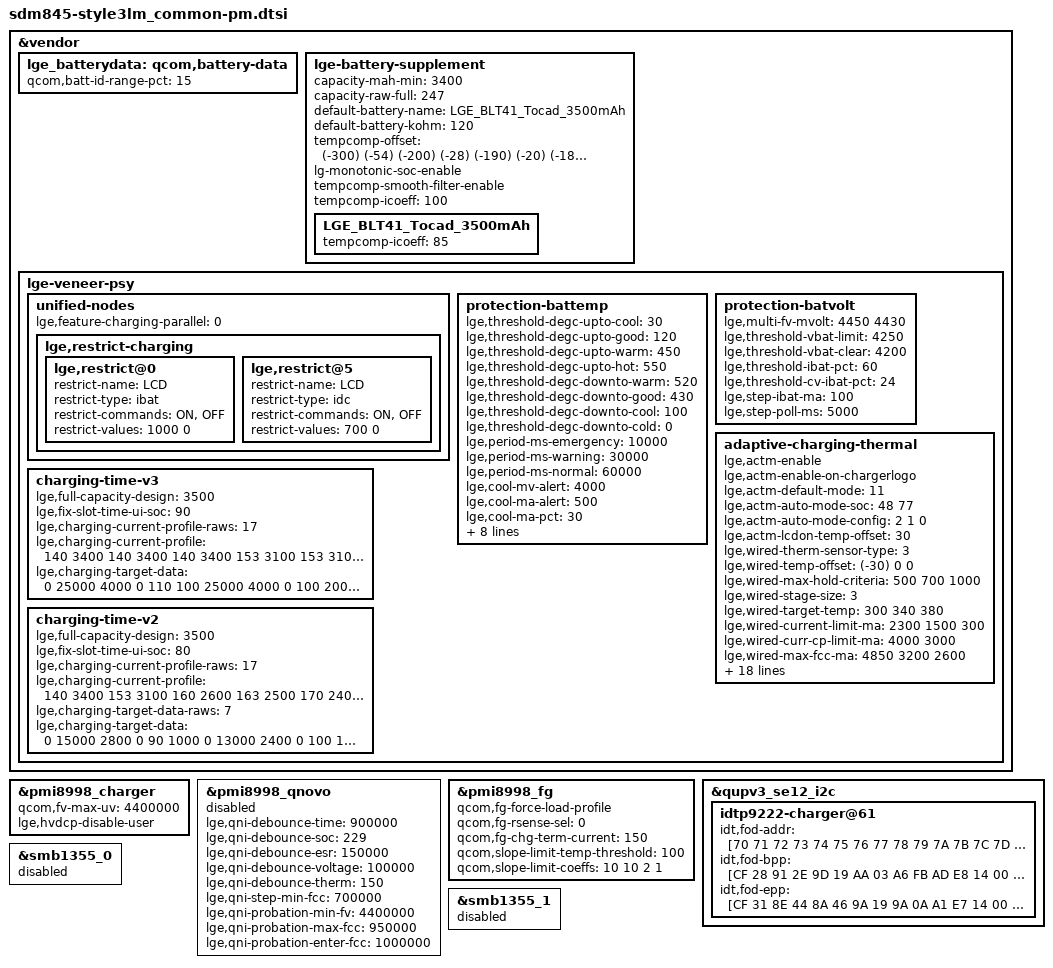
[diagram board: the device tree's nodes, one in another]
/* Copyright (c) 2017, The Linux Foundation. All rights reserved.
 *
 * This program is free software; you can redistribute it and/or modify
 * it under the terms of the GNU General Public License version 2 and
 * only version 2 as published by the Free Software Foundation.
 *
 * This program is distributed in the hope that it will be useful,
 * but WITHOUT ANY WARRANTY; without even the implied warranty of
 * MERCHANTABILITY or FITNESS FOR A PARTICULAR PURPOSE.  See the
 * GNU General Public License for more details.
 */

#include "../sdm845-judy_common/sdm845-judy_common-pm.dtsi"

&vendor {
	lge_batterydata: qcom,battery-data {
		qcom,batt-id-range-pct = <15>;
		#include "../../sdm845-battery/LGE_BLT41_Tocad_3500mAh.dtsi"
	};

	lge-battery-supplement {
		capacity-mah-min = <3400>;
		capacity-raw-full = <247>;

		default-battery-name = "LGE_BLT41_Tocad_3500mAh";
		default-battery-kohm = <120>;

		/* format : (temp index) (temp delta) */
		tempcomp-offset = <
			(-300) (-54)
			(-200) (-28)
			(-190) (-20)
			(-180) (-12)
			(-170) ( -8)
			(-160) ( -4)
			(-150)    0
			(-100)    8
			(-50)     9
			0         8
			50        6
			100       1
			150    ( -4)
			200    ( -9)
			250    (-12)
			300    (-21)
			350    (-26)
			400    (-31)
			450    (-34)
			500    (-32)
			550    (-30)
			600    (-24)
			700    (-11)
			800    (-11)
			900    (-11)
		>;

		//tempcomp-qnovo-charging;
		lg-monotonic-soc-enable;

		tempcomp-smooth-filter-enable;
		tempcomp-icoeff = <100>;
		LGE_BLT41_Tocad_3500mAh {
			tempcomp-icoeff = <85>;
		};
	};

	lge-veneer-psy {
		unified-nodes {
			lge,feature-charging-parallel = <0>;

			lge,restrict-charging {
				lge,restrict@0 {
					restrict-name = "LCD";
					restrict-type = "ibat";
					restrict-commands = "ON", "OFF";
					restrict-values = <1000      0>;
				};

				lge,restrict@5 {
					restrict-name = "LCD";
					restrict-type = "idc";
					restrict-commands = "ON", "OFF";
					restrict-values = < 700      0>;
				};
			};
		};

		protection-battemp {
			lge,threshold-degc-upto-cool = <30>;
			lge,threshold-degc-upto-good = <120>;
			lge,threshold-degc-upto-warm = <450>;
			lge,threshold-degc-upto-hot = <550>;
			lge,threshold-degc-downto-warm = <520>;
			lge,threshold-degc-downto-good = <430>;
			lge,threshold-degc-downto-cool = <100>;
			lge,threshold-degc-downto-cold = <0>;

			lge,period-ms-emergency	= <10000>;
			lge,period-ms-warning	= <30000>;
			lge,period-ms-normal	= <60000>;

		// parameters for warning status cool and warm
			lge,cool-mv-alert	= <4000>;
			lge,cool-ma-alert	= <500>;	// fixed 500 mA
			lge,cool-ma-pct		= <30>;		// means 0.3C rate

			lge,warm-mv-float	= <4000>;
			lge,warm-ma-pct		= <50>;		// means 0.5C rate

		// parameters for battery protection at chilly status
			lge,chilly-status-support;
			lge,chilly-degc-lowerbound = <0>;
			lge,chilly-degc-upperbound = <150>;
			lge,chilly-mv-alert	   = <4000>;
			lge,chilly-ma-alert	   = <500>;
			lge,chilly-ma-pct	   = <50>; 	// means 0.5C rate under batvol 4V
		};

		protection-batvolt {
			//lge,mulit-fv-enable;
			lge,multi-fv-mvolt = <4450 4430>;   // <CC_FV, CV_FV>

			lge,threshold-vbat-limit = <4250>;
			lge,threshold-vbat-clear = <4200>;
			lge,threshold-ibat-pct = <60>;      // means 0.6C rate
			lge,threshold-cv-ibat-pct = <24>;   // means 0.24C = 3400 * 0.24 = 816mA, CV = UI-100%

			lge,step-ibat-ma = <100>;
			lge,step-poll-ms = <5000>;
		};

		adaptive-charging-thermal {
			lge,actm-enable;
			//lge,actm-enable-cp-charging;                 // whether cp charging is supported.
			lge,actm-enable-on-chargerlogo;                // the actm operates charging first mode in chargerlogo
			lge,actm-default-mode = <11>;                  // 0-thermal first, 1-balanced, 2-charging first, 3-auto
			/*  actm auto mode description
			 *                     48%            77%
			 *    2-charging first  |  1-balacned  |  0-thermal first */
			lge,actm-auto-mode-soc = <48 77>;              // those values are raw soc.
			lge,actm-auto-mode-config = <2 1 0>;           // <2 1 0> means actm mode
			lge,actm-lcdon-temp-offset = <30>;             // unit: 0.1 degree

			lge,wired-therm-sensor-type = <3>;             // bit(0)-BATT, bit(1)-VTS
			lge,wired-temp-offset = <(-30) 0 0>;           // thermal first, balanced, charging first
			lge,wired-max-hold-criteria = <500 700 1000>;  // allow rising 1 degree per 20/14/10/min
			lge,wired-stage-size = <3>;
			lge,wired-target-temp = <300 340 380>;
			lge,wired-current-limit-ma = <2300 1500 300>;
			lge,wired-curr-cp-limit-ma = <4000 3000>;      // extension of lge,wired-current-limit-ma
                                                           // 0-pps, 1-qc3.0
			lge,wired-max-fcc-ma = <4850 3200 2600>;       // 0-pps ta, 1- qc3.0 ta, 2-qc2.0 ta
			lge,wired-current-step-size = <3>;
			lge,wired-current-step-temp = <5 15 30>;
			lge,wired-current-step-ma = <100 200 400>;
			lge,wired-timer-ms = <60000>;

			lge,wireless-therm-sensor-type = <1>;           // bit(0)-BATT, bit(1)-VTS
			lge,wireless-temp-offset = <(-30) 0 0>;         // thermal first, balanced, charging first
			lge,wireless-max-hold-criteria = <250 333 500>; // allow rising 1 degree per 40/30/20min
			lge,wireless-stage-size = <3>;
			lge,wireless-target-temp = <340 380 415>;
			lge,wireless-epp-power-limit-mw = <6300 4050 3000>;
			lge,wireless-bpp-power-limit-mw = <4200 3900 3000>;
			lge,wireless-power-step-size = <3>;
			lge,wireless-power-step-temp = <5 15 30>;
			lge,wireless-epp-power-step-mw = <450 900 1350>;
			lge,wireless-bpp-power-step-mw = <300 600 900>;
			lge,wireless-timer-ms = <60000>;
		};

		charging-time-v3 {
			lge,full-capacity-design = <3500>;
			lge,fix-slot-time-ui-soc = <90>;

			lge,charging-current-profile-raws = <17>;  /* max: 20 */
			lge,charging-current-profile = <
			/* format: raw_soc, raw_current(mA) */
			/* | Thermal |  | Balanced | | Charging | */
				140  3400    140  3400    140  3400
				153  3100    153  3100    153  3100
				160  2600    160  2600    160  2600
				163  2500    163  2500    163  2500
				170  2400    170  2400    170  2400
				171  2300    171  2300    171  2300
				174  2200    174  2200    174  2200
				177  2100    177  2100    177  2100
				192  2000    192  2000    192  2000
				217  1850    217  1850    217  1850
				225  1550    225  1550    225  1550
				232  1300    232  1300    232  1300
				237  1100    237  1100    237  1100
				241   900    241   900    241   900
				242   800    242   800    242   800
				245   700    245   700    245   700
				247   600    247   600    247   600   /* <- END -> */
			>;

			lge,charging-target-data = <
	/* format : type, power(mW), current(mA), down(uA), target(min) */
	/* cp pps  thermal  */    0    25000    4000       0    110
	/*         balanced */  100    25000    4000       0    100
	/*         charging */  200    25000    4850       0     90
	/* CP QC3  thermal  */    1    16200    3000       0    125
	/*         balanced */  101    16200    3000       0    115
	/*         charging */  201    16200    3200       0    105
	/*               >>>>> upper is for SMB1390 <<<<<               */
	/* QC2     thermal  */    2    13000    2300       0    110
	/*         balanced */  102    13000    2300       0    100
	/*         charging */  202    15000    2600       0     90
	/* DCP     thermal  */    2     7500    1650     881    150
	/*         balanced */  102     7500    1650     881    150
	/*         charging */  202     7500    1650     881    150
	/* SDP     thermal  */    2     2500     500       0    425
	/*         balanced */  102     2500     500       0    425
	/*         charging */  202     2500     500       0    425
	/* WLC EPP thermal  */    3     7200    1750    2224    200
	/*         balanced */  103     7200    1750    2224    200
	/*         charging */  203     7200    1750    1032    175
	/* WLC BPP thermal  */    3     4500    1100     920    280
	/*         balanced */  103     4500    1100     920    280
	/*         charging */  203     4500    1100     640    265
	/* BCC     thermal  */    4    12500    2500       0    125
	/*         balanced */  104    12500    2500       0    125
	/*         charging */  204    12500    2500       0    125
			>;
		};

		charging-time-v2 {
			lge,full-capacity-design = <3500>;
			lge,fix-slot-time-ui-soc = <80>;
			lge,charging-current-profile-raws = <17>;
			lge,charging-current-profile = <
				/* format: raw_soc, raw_current(mA) */
				/* CC */
				140  3400
				153  3100
				160  2600
				163  2500
				170  2400
				171  2300
				174  2200
				177  2100
				192  2000
				217  1850
				225  1550
				232  1300
				237  1100
				241  900
				242  800
				245  700
				247  600   /* <- END -> */
			>;

			lge,charging-target-data-raws = <7>;
			lge,charging-target-data = <
			/* format : type, power(mW), current(mA), down(uA), target(min), no_dd_decipct */
			/* 0-type-wired: chargerlogo */   0    15000    2800       0     90    1000
			/* 1-type-wired: power on    */   0    13000    2400       0    100    1000
			/* 2-type-wired: DCP         */   0     7500    1650    1100    150    1000
			/* 3-type-wired: SDP         */   0     2500     500       0    425    1000
			/* 4-type-wireless: EPP      */   1     7200    1068     622    195    1000
			/* 5-type-wireless: BPP      */   1     4500     992     527    215    1000
			/* 6-type-BCC                */   2     7500    1500       0    140    1000
			>;
		};
	};
};

&pmi8998_charger {
	qcom,fv-max-uv = <4400000>;
	lge,hvdcp-disable-user;
};

&pmi8998_qnovo {
	status = "disabled";
	//lge,enable-qni-debounce;
	lge,qni-debounce-time = <900000>;
	lge,qni-debounce-soc = <229>;
	lge,qni-debounce-esr = <150000>;
	lge,qni-debounce-voltage = <100000>;
	lge,qni-debounce-therm = <150>;

	//lge,enable-qni-probation;
	lge,qni-step-min-fcc = <700000>;
	lge,qni-probation-min-fv = <4400000>;
	lge,qni-probation-max-fcc = <950000>;
	lge,qni-probation-enter-fcc = <1000000>;
};

&pmi8998_fg {
	qcom,fg-force-load-profile;
	qcom,fg-rsense-sel = <0>;
	qcom,fg-chg-term-current = <150>;
	qcom,slope-limit-temp-threshold = <100>;
	qcom,slope-limit-coeffs = <10 10 2 1>;
	/*
	 * Element 0 - Low temp dischg
	 * Element 1 - Low temp chg
	 * Element 2 - High temp dischg
	 * Element 3 - High temp chg
	 * Each msoc percent takes at least 1%/(0.012207%*value*8) * 1.47s.
	 * Possible values are from 0 to 31.
	 */
};

&qupv3_se12_i2c {
	idtp9222-charger@61 {
		// FOD parameters
		idt,fod-addr = [70 71 72 73 74 75 76 77 78 79 7A 7B 7C 7D 7E 7F];
		idt,fod-bpp  = [CF 28 91 2E 9D 19 AA 03 A6 FB AD E8 14 00 00 00];
		idt,fod-epp  = [CF 31 8E 44 8A 46 9A 19 9A 0A A1 E7 14 00 64 32];
	};
};

&smb1355_0 {
	status = "disabled";
};

&smb1355_1 {
	status = "disabled";
};
